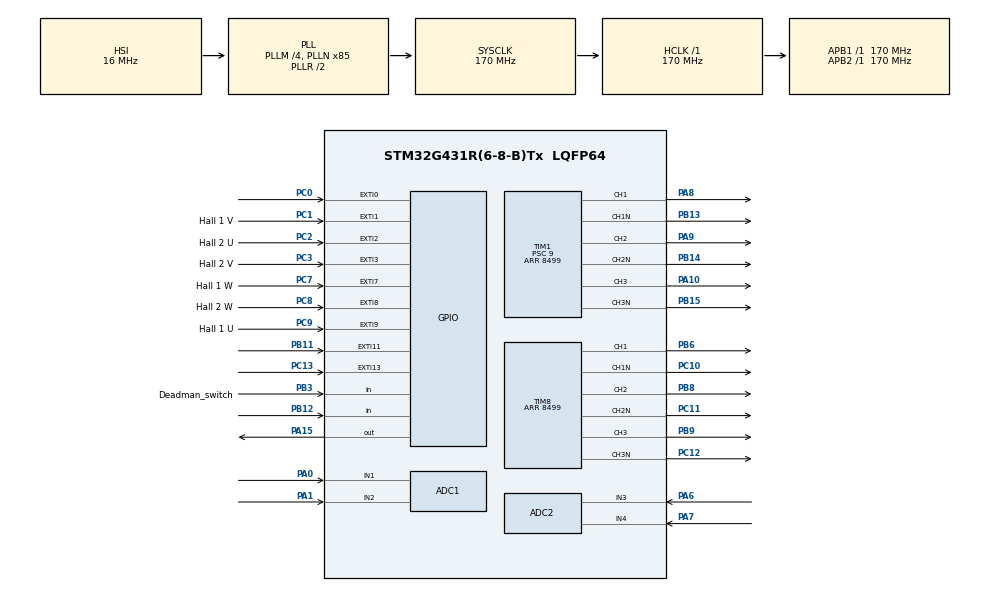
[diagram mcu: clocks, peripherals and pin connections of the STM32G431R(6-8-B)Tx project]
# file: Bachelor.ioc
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ADC1.Channel-0\#ChannelRegularConversion=ADC_CHANNEL_1
ADC1.NbrOfConversionFlag=1
ADC1.OffsetNumber-0\#ChannelRegularConversion=ADC_OFFSET_NONE
ADC1.Rank-0\#ChannelRegularConversion=1
ADC1.SamplingTime-0\#ChannelRegularConversion=ADC_SAMPLETIME_2CYCLES_5
ADC1.master=1
ADC2.Channel-0\#ChannelRegularConversion=ADC_CHANNEL_3
ADC2.NbrOfConversionFlag=1
ADC2.OffsetNumber-0\#ChannelRegularConversion=ADC_OFFSET_NONE
ADC2.Rank-0\#ChannelRegularConversion=1
ADC2.SamplingTime-0\#ChannelRegularConversion=ADC_SAMPLETIME_2CYCLES_5
Dma.ADC1.0.Direction=DMA_PERIPH_TO_MEMORY
Dma.ADC1.0.EventEnable=DISABLE
Dma.ADC1.0.Instance=DMA1_Channel1
Dma.ADC1.0.MemDataAlignment=DMA_MDATAALIGN_HALFWORD
Dma.ADC1.0.MemInc=DMA_MINC_ENABLE
Dma.ADC1.0.Mode=DMA_CIRCULAR
Dma.ADC1.0.PeriphDataAlignment=DMA_PDATAALIGN_HALFWORD
Dma.ADC1.0.PeriphInc=DMA_PINC_DISABLE
Dma.ADC1.0.Polarity=HAL_DMAMUX_REQ_GEN_RISING
Dma.ADC1.0.Priority=DMA_PRIORITY_LOW
Dma.ADC1.0.RequestNumber=1
Dma.ADC1.0.SignalID=NONE
Dma.ADC1.0.SyncEnable=DISABLE
Dma.ADC1.0.SyncPolarity=HAL_DMAMUX_SYNC_NO_EVENT
Dma.ADC1.0.SyncRequestNumber=1
Dma.ADC1.0.SyncSignalID=NONE
Dma.ADC2.1.Direction=DMA_PERIPH_TO_MEMORY
Dma.ADC2.1.EventEnable=DISABLE
Dma.ADC2.1.Instance=DMA1_Channel2
Dma.ADC2.1.MemDataAlignment=DMA_MDATAALIGN_HALFWORD
Dma.ADC2.1.MemInc=DMA_MINC_ENABLE
Dma.ADC2.1.Mode=DMA_CIRCULAR
Dma.ADC2.1.PeriphDataAlignment=DMA_PDATAALIGN_HALFWORD
Dma.ADC2.1.PeriphInc=DMA_PINC_DISABLE
Dma.ADC2.1.Polarity=HAL_DMAMUX_REQ_GEN_RISING
Dma.ADC2.1.Priority=DMA_PRIORITY_LOW
Dma.ADC2.1.RequestNumber=1
Dma.ADC2.1.SignalID=NONE
Dma.ADC2.1.SyncEnable=DISABLE
Dma.ADC2.1.SyncPolarity=HAL_DMAMUX_SYNC_NO_EVENT
Dma.ADC2.1.SyncRequestNumber=1
Dma.ADC2.1.SyncSignalID=NONE
Dma.Request0=ADC1
Dma.Request1=ADC2
FREERTOS.Tasks01=defaultTask,24,128,StartDefaultTask,Default,NULL,Dynamic,NULL,NULL
FREERTOS.configUSE_NEWLIB_REENTRANT=1
Mcu.Family=STM32G4
Mcu.Name=STM32G431R(6-8-B)Tx
Mcu.Package=LQFP64
NUCLEO-G431RB.BUTTON=1
NUCLEO-G431RB.LD1=true
NUCLEO-G431RB.VCP=true
NVIC.DMA1_Channel1_IRQn=true\:5\:0\:false\:false\:true\:true\:false\:true\:true
NVIC.DMA1_Channel2_IRQn=true\:5\:0\:false\:false\:true\:true\:false\:true\:true
NVIC.EXTI0_IRQn=true\:5\:0\:false\:false\:true\:true\:true\:true\:true
NVIC.EXTI15_10_IRQn=true\:5\:0\:false\:false\:true\:true\:false\:true\:true
NVIC.EXTI1_IRQn=true\:5\:0\:false\:false\:true\:true\:true\:true\:true
NVIC.EXTI2_IRQn=true\:5\:0\:false\:false\:true\:true\:true\:true\:true
NVIC.EXTI3_IRQn=true\:5\:0\:false\:false\:true\:true\:true\:true\:true
NVIC.PriorityGroup=NVIC_PRIORITYGROUP_4
NVIC.TIM7_IRQn=true\:15\:0\:false\:false\:true\:false\:false\:true\:true
NVIC.TimeBase=TIM7_IRQn
NVIC.TimeBaseIP=TIM7
PA0.Mode=IN1-Single-Ended
PA0.Signal=ADC1_IN1
PA1.Mode=IN2-Single-Ended
PA1.Signal=ADC1_IN2
PA10.Signal=S_TIM1_CH3
PA13.GPIO_Label=T_SWDIO
PA13.Mode=Serial_Wire
PA13.Signal=SYS_JTMS-SWDIO
PA14.GPIO_Label=T_SWCLK
PA14.Mode=Serial_Wire
PA14.Signal=SYS_JTCK-SWCLK
PA15.Signal=GPIO_Output
PA2.Signal=LPUART1_TX
PA3.Signal=LPUART1_RX
PA5.Signal=ADC2_IN13
PA6.Mode=IN3-Single-Ended
PA6.Signal=ADC2_IN3
PA7.Mode=IN4-Single-Ended
PA7.Signal=ADC2_IN4
PA8.Signal=S_TIM1_CH1
PA9.Signal=S_TIM1_CH2
PB11.Signal=GPXTI11
PB12.GPIO_PuPd=GPIO_PULLUP
PB12.Signal=GPIO_Input
PB13.Mode=PWM Generation1 CH1 CH1N
PB13.Signal=TIM1_CH1N
PB14.Mode=PWM Generation2 CH2 CH2N
PB14.Signal=TIM1_CH2N
PB15.Mode=PWM Generation3 CH3 CH3N
PB15.Signal=TIM1_CH3N
PB3.GPIO_Label=Deadman_switch
PB3.GPIO_PuPd=GPIO_PULLUP
PB3.Signal=GPIO_Input
PB6.Signal=S_TIM8_CH1
PB8-BOOT0.Signal=S_TIM8_CH2
PB9.Signal=S_TIM8_CH3
PC0.GPIO_PuPd=GPIO_PULLUP
PC0.Signal=GPXTI0
PC1.GPIO_Label=Hall 1 V
PC1.GPIO_PuPd=GPIO_NOPULL
PC1.Signal=GPXTI1
PC10.Mode=PWM Generation1 CH1 CH1N
PC10.Signal=TIM8_CH1N
PC11.Mode=PWM Generation2 CH2 CH2N
PC11.Signal=TIM8_CH2N
PC12.Mode=PWM Generation3 CH3 CH3N
PC12.Signal=TIM8_CH3N
PC13.Signal=GPXTI13
PC14-OSC32_IN.GPIO_Label=RCC_OSC32_OUT
PC14-OSC32_IN.Signal=RCC_OSC32_IN
PC15-OSC32_OUT.GPIO_Label=RCC_OSC32_OUT
PC15-OSC32_OUT.Signal=RCC_OSC32_OUT
PC2.GPIO_Label=Hall 2 U
PC2.GPIO_PuPd=GPIO_NOPULL
PC2.Signal=GPXTI2
PC3.GPIO_Label=Hall 2 V
PC3.GPIO_PuPd=GPIO_NOPULL
PC3.Signal=GPXTI3
PC5.Signal=ADC2_IN11
PC7.GPIO_Label=Hall 1 W
PC7.GPIO_PuPd=GPIO_NOPULL
PC7.Signal=GPXTI7
PC8.GPIO_Label=Hall 2 W
PC8.GPIO_PuPd=GPIO_NOPULL
PC8.Signal=GPXTI8
PC9.GPIO_Label=Hall 1 U
PC9.GPIO_PuPd=GPIO_NOPULL
PC9.Signal=GPXTI9
PF0-OSC_IN.GPIO_Label=RCC_OSC_IN
PF0-OSC_IN.Signal=RCC_OSC_IN
PF1-OSC_OUT.GPIO_Label=RCC_OSC_OUT
PF1-OSC_OUT.Signal=RCC_OSC_OUT
ProjectManager.HeapSize=0x200
ProjectManager.StackSize=0x400
ProjectManager.TargetToolchain=STM32CubeIDE
RCC.ADC12Freq_Value=170000000
RCC.AHBFreq_Value=170000000
RCC.APB1Freq_Value=170000000
RCC.APB1TimFreq_Value=170000000
RCC.APB2Freq_Value=170000000
RCC.APB2TimFreq_Value=170000000
RCC.CortexFreq_Value=170000000
RCC.EXTERNAL_CLOCK_VALUE=12288000
RCC.HCLKFreq_Value=170000000
RCC.HSE_VALUE=24000000
RCC.HSI48_VALUE=48000000
RCC.HSI_VALUE=16000000
RCC.LSE_VALUE=32768
RCC.PLLM=RCC_PLLM_DIV4
RCC.PLLN=85
RCC.RTCClockSelection=RCC_RTCCLKSOURCE_LSE
RCC.SYSCLKFreq_VALUE=170000000
RCC.SYSCLKSource=RCC_SYSCLKSOURCE_PLLCLK
RCC.USBFreq_Value=170000000
RCC.VCOOutputFreq_Value=340000000
SH.S_TIM1_CH1.0=TIM1_CH1,PWM Generation1 CH1 CH1N
SH.S_TIM1_CH2.0=TIM1_CH2,PWM Generation2 CH2 CH2N
SH.S_TIM1_CH3.0=TIM1_CH3,PWM Generation3 CH3 CH3N
SH.S_TIM8_CH1.0=TIM8_CH1,PWM Generation1 CH1 CH1N
SH.S_TIM8_CH2.0=TIM8_CH2,PWM Generation2 CH2 CH2N
SH.S_TIM8_CH3.0=TIM8_CH3,PWM Generation3 CH3 CH3N
TIM1.AsymmetricalDeadTime=ENABLE
TIM1.AutoReloadPreload=TIM_AUTORELOAD_PRELOAD_ENABLE
TIM1.BreakPolarity=TIM_BREAKPOLARITY_LOW
TIM1.BreakState=TIM_BREAK_DISABLE
TIM1.Channel-PWM\ Generation1\ CH1\ CH1N=TIM_CHANNEL_1
TIM1.Channel-PWM\ Generation2\ CH2\ CH2N=TIM_CHANNEL_2
TIM1.Channel-PWM\ Generation3\ CH3\ CH3N=TIM_CHANNEL_3
TIM1.DeadTime=68
TIM1.OffStateIDLEMode=TIM_OSSI_ENABLE
TIM1.OffStateRunMode=TIM_OSSR_ENABLE
TIM1.PeriodNoDither=8499
TIM1.Prescaler=9
TIM1.PulseNoDither_1=2733
TIM8.AutoReloadPreload=TIM_AUTORELOAD_PRELOAD_ENABLE
TIM8.Channel-PWM\ Generation1\ CH1\ CH1N=TIM_CHANNEL_1
TIM8.Channel-PWM\ Generation2\ CH2\ CH2N=TIM_CHANNEL_2
TIM8.Channel-PWM\ Generation3\ CH3\ CH3N=TIM_CHANNEL_3
TIM8.DeadTime=68
TIM8.OffStateIDLEMode=TIM_OSSI_ENABLE
TIM8.OffStateRunMode=TIM_OSSR_ENABLE
TIM8.PeriodNoDither=8499
VP_FREERTOS_VS_CMSIS_V2.Mode=CMSIS_V2
VP_NUCLEO-G431RB_VS_BSP_COMMON.Mode=COMMON
VP_SYS_VS_DBSignals.Mode=DisableDeadBatterySignals
VP_SYS_VS_tim7.Mode=TIM7
VP_TIM1_VS_ClockSourceINT.Mode=Internal
VP_TIM8_VS_ClockSourceINT.Mode=Internal
board=NUCLEO-G431RB

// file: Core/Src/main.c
/* USER CODE BEGIN Header */
/**
  ******************************************************************************
  * @file           : main.c
  * @brief          : Main program body
  ******************************************************************************
  * @attention
  *
  * Copyright (c) 2026 STMicroelectronics.
  * All rights reserved.
  *
  * This software is licensed under terms that can be found in the LICENSE file
  * in the root directory of this software component.
  * If no LICENSE file comes with this software, it is provided AS-IS.
  *
  ******************************************************************************
  */
/* USER CODE END Header */
#include "main.h"
#include "cmsis_os.h"
#include "adc.h"
#include "dma.h"
#include "tim.h"
#include "gpio.h"

/* USER CODE BEGIN Includes */
#include "pwm_control.h"
#include "myapp.h"
/* USER CODE END Includes */

COM_InitTypeDef BspCOMInit;

void SystemClock_Config(void);
void MX_FREERTOS_Init(void);

int main(void)
{

  /* MCU Configuration--------------------------------------------------------*/

  /* Reset of all peripherals, Initializes the Flash interface and the Systick. */
  HAL_Init();

  /* Configure the system clock */
  SystemClock_Config();

  /* Initialize all configured peripherals */
  MX_GPIO_Init();
  MX_DMA_Init();
  MX_TIM1_Init();
  MX_TIM8_Init();
  MX_ADC1_Init();
  MX_ADC2_Init();
  /* USER CODE BEGIN 2 */
  App_Init();
  /* USER CODE END 2 */

  /* Init scheduler */
  osKernelInitialize();  /* Call init function for freertos objects (in cmsis_os2.c) */
  MX_FREERTOS_Init();

  /* Initialize leds */
  BSP_LED_Init(LED_GREEN);

  /* Initialize USER push-button, will be used to trigger an interrupt each time it's pressed.*/
  BSP_PB_Init(BUTTON_USER, BUTTON_MODE_EXTI);

  /* Initialize COM1 port (115200, 8 bits (7-bit data + 1 stop bit), no parity */
  BspCOMInit.BaudRate   = 115200;
  BspCOMInit.WordLength = COM_WORDLENGTH_8B;
  BspCOMInit.StopBits   = COM_STOPBITS_1;
  BspCOMInit.Parity     = COM_PARITY_NONE;
  BspCOMInit.HwFlowCtl  = COM_HWCONTROL_NONE;
  if (BSP_COM_Init(COM1, &BspCOMInit) != BSP_ERROR_NONE)
  {
    Error_Handler();
  }

  /* Start scheduler */
  osKernelStart();

  /* We should never get here as control is now taken by the scheduler */

  /* Infinite loop */
  /* USER CODE BEGIN WHILE */
  while (1)
  {
    App_Run();
    /* USER CODE END WHILE */

  }
}

void SystemClock_Config(void)
{
  RCC_OscInitTypeDef RCC_OscInitStruct = {0};
  RCC_ClkInitTypeDef RCC_ClkInitStruct = {0};

  /** Configure the main internal regulator output voltage
  */
  HAL_PWREx_ControlVoltageScaling(PWR_REGULATOR_VOLTAGE_SCALE1_BOOST);

  /** Initializes the RCC Oscillators according to the specified parameters
  * in the RCC_OscInitTypeDef structure.
  */
  RCC_OscInitStruct.OscillatorType = RCC_OSCILLATORTYPE_HSI;
  RCC_OscInitStruct.HSIState = RCC_HSI_ON;
  RCC_OscInitStruct.HSICalibrationValue = RCC_HSICALIBRATION_DEFAULT;
  RCC_OscInitStruct.PLL.PLLState = RCC_PLL_ON;
  RCC_OscInitStruct.PLL.PLLSource = RCC_PLLSOURCE_HSI;
  RCC_OscInitStruct.PLL.PLLM = RCC_PLLM_DIV4;
  RCC_OscInitStruct.PLL.PLLN = 85;
  RCC_OscInitStruct.PLL.PLLP = RCC_PLLP_DIV2;
  RCC_OscInitStruct.PLL.PLLQ = RCC_PLLQ_DIV2;
  RCC_OscInitStruct.PLL.PLLR = RCC_PLLR_DIV2;
  if (HAL_RCC_OscConfig(&RCC_OscInitStruct) != HAL_OK)
  {
    Error_Handler();
  }

  /** Initializes the CPU, AHB and APB buses clocks
  */
  RCC_ClkInitStruct.ClockType = RCC_CLOCKTYPE_HCLK|RCC_CLOCKTYPE_SYSCLK
                              |RCC_CLOCKTYPE_PCLK1|RCC_CLOCKTYPE_PCLK2;
  RCC_ClkInitStruct.SYSCLKSource = RCC_SYSCLKSOURCE_PLLCLK;
  RCC_ClkInitStruct.AHBCLKDivider = RCC_SYSCLK_DIV1;
  RCC_ClkInitStruct.APB1CLKDivider = RCC_HCLK_DIV1;
  RCC_ClkInitStruct.APB2CLKDivider = RCC_HCLK_DIV1;

  if (HAL_RCC_ClockConfig(&RCC_ClkInitStruct, FLASH_LATENCY_4) != HAL_OK)
  {
    Error_Handler();
  }
}

void HAL_TIM_PeriodElapsedCallback(TIM_HandleTypeDef *htim)
{
  if (htim->Instance == TIM7)
  {
    HAL_IncTick();
  }
}

void Error_Handler(void)
{
  __disable_irq();
  while (1)
  {
  }
}

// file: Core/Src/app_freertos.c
/* USER CODE BEGIN Header */
/**
  ******************************************************************************
  * File Name          : app_freertos.c
  * Description        : Code for freertos applications
  ******************************************************************************
  * @attention
  *
  * Copyright (c) 2026 STMicroelectronics.
  * All rights reserved.
  *
  * This software is licensed under terms that can be found in the LICENSE file
  * in the root directory of this software component.
  * If no LICENSE file comes with this software, it is provided AS-IS.
  *
  ******************************************************************************
  */
/* USER CODE END Header */

#include "FreeRTOS.h"
#include "task.h"
#include "main.h"
#include "cmsis_os.h"

/* USER CODE BEGIN Includes */
#include "app_default_task.h"
#include "myapp.h"

/* USER CODE END Includes */

/* Definitions for defaultTask */
osThreadId_t defaultTaskHandle;
const osThreadAttr_t defaultTask_attributes = {
  .name = "defaultTask",
  .priority = (osPriority_t) osPriorityNormal,
  .stack_size = 128 * 4
};

void StartDefaultTask(void *argument);

void MX_FREERTOS_Init(void); /* (MISRA C 2004 rule 8.1) */

void MX_FREERTOS_Init(void) {
  /* USER CODE BEGIN Init */
  App_StartTasks();

  /* USER CODE END Init */

  /* Create the thread(s) */
  /* creation of defaultTask */
  defaultTaskHandle = osThreadNew(StartDefaultTask, NULL, &defaultTask_attributes);

}

void StartDefaultTask(void *argument)
{
  /* USER CODE BEGIN StartDefaultTask */
  AppDefaultTask_Run(argument);
  /* USER CODE END StartDefaultTask */
}
